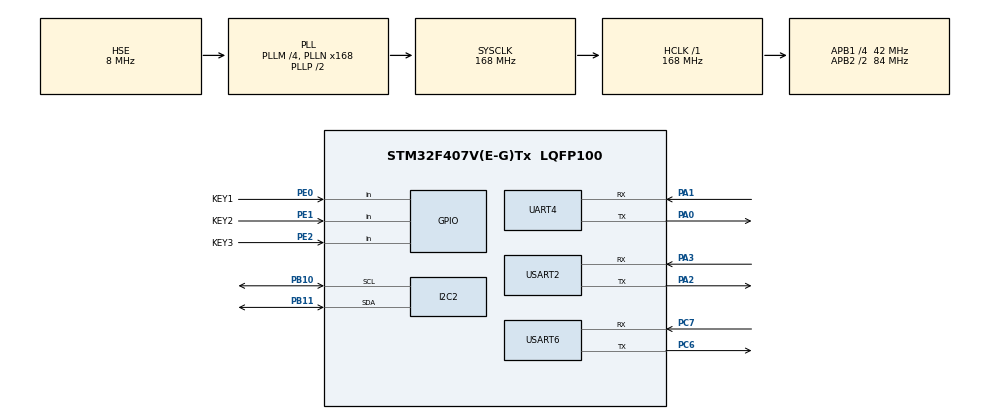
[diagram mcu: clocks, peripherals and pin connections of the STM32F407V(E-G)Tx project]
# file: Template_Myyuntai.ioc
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Dma.Request0=UART4_RX
Dma.Request1=USART2_RX
Dma.Request2=USART6_RX
Dma.UART4_RX.0.Direction=DMA_PERIPH_TO_MEMORY
Dma.UART4_RX.0.FIFOMode=DMA_FIFOMODE_DISABLE
Dma.UART4_RX.0.Instance=DMA1_Stream2
Dma.UART4_RX.0.MemDataAlignment=DMA_MDATAALIGN_BYTE
Dma.UART4_RX.0.MemInc=DMA_MINC_ENABLE
Dma.UART4_RX.0.Mode=DMA_NORMAL
Dma.UART4_RX.0.PeriphDataAlignment=DMA_PDATAALIGN_BYTE
Dma.UART4_RX.0.PeriphInc=DMA_PINC_DISABLE
Dma.UART4_RX.0.Priority=DMA_PRIORITY_LOW
Dma.USART2_RX.1.Direction=DMA_PERIPH_TO_MEMORY
Dma.USART2_RX.1.FIFOMode=DMA_FIFOMODE_DISABLE
Dma.USART2_RX.1.Instance=DMA1_Stream5
Dma.USART2_RX.1.MemDataAlignment=DMA_MDATAALIGN_BYTE
Dma.USART2_RX.1.MemInc=DMA_MINC_ENABLE
Dma.USART2_RX.1.Mode=DMA_NORMAL
Dma.USART2_RX.1.PeriphDataAlignment=DMA_PDATAALIGN_BYTE
Dma.USART2_RX.1.PeriphInc=DMA_PINC_DISABLE
Dma.USART2_RX.1.Priority=DMA_PRIORITY_LOW
Dma.USART6_RX.2.Direction=DMA_PERIPH_TO_MEMORY
Dma.USART6_RX.2.FIFOMode=DMA_FIFOMODE_DISABLE
Dma.USART6_RX.2.Instance=DMA2_Stream1
Dma.USART6_RX.2.MemDataAlignment=DMA_MDATAALIGN_BYTE
Dma.USART6_RX.2.MemInc=DMA_MINC_ENABLE
Dma.USART6_RX.2.Mode=DMA_NORMAL
Dma.USART6_RX.2.PeriphDataAlignment=DMA_PDATAALIGN_BYTE
Dma.USART6_RX.2.PeriphInc=DMA_PINC_DISABLE
Dma.USART6_RX.2.Priority=DMA_PRIORITY_LOW
Mcu.Family=STM32F4
Mcu.Name=STM32F407V(E-G)Tx
Mcu.Package=LQFP100
NVIC.DMA1_Stream2_IRQn=true\:0\:0\:false\:false\:true\:false\:true\:true
NVIC.DMA1_Stream5_IRQn=true\:0\:0\:false\:false\:true\:false\:true\:true
NVIC.DMA2_Stream1_IRQn=true\:0\:0\:false\:false\:true\:false\:true\:true
NVIC.PriorityGroup=NVIC_PRIORITYGROUP_4
NVIC.TIM2_IRQn=true\:0\:0\:false\:false\:true\:true\:true\:true
NVIC.UART4_IRQn=true\:2\:0\:true\:false\:true\:true\:true\:true
NVIC.USART2_IRQn=true\:2\:0\:true\:false\:true\:true\:true\:true
NVIC.USART6_IRQn=true\:0\:0\:false\:false\:true\:true\:true\:true
PA0-WKUP.Mode=Asynchronous
PA0-WKUP.Signal=UART4_TX
PA1.Mode=Asynchronous
PA1.Signal=UART4_RX
PA2.Mode=Asynchronous
PA2.Signal=USART2_TX
PA3.Mode=Asynchronous
PA3.Signal=USART2_RX
PB10.Mode=I2C
PB10.Signal=I2C2_SCL
PB11.Mode=I2C
PB11.Signal=I2C2_SDA
PC14-OSC32_IN.Mode=LSE-External-Oscillator
PC14-OSC32_IN.Signal=RCC_OSC32_IN
PC15-OSC32_OUT.Mode=LSE-External-Oscillator
PC15-OSC32_OUT.Signal=RCC_OSC32_OUT
PC6.Mode=Asynchronous
PC6.Signal=USART6_TX
PC7.Mode=Asynchronous
PC7.Signal=USART6_RX
PE0.GPIO_Label=KEY1
PE0.GPIO_PuPd=GPIO_PULLUP
PE0.Signal=GPIO_Input
PE1.GPIO_Label=KEY2
PE1.GPIO_PuPd=GPIO_PULLUP
PE1.Signal=GPIO_Input
PE2.GPIO_Label=KEY3
PE2.GPIO_PuPd=GPIO_PULLUP
PE2.Signal=GPIO_Input
PH0-OSC_IN.Mode=HSE-External-Oscillator
PH0-OSC_IN.Signal=RCC_OSC_IN
PH1-OSC_OUT.Mode=HSE-External-Oscillator
PH1-OSC_OUT.Signal=RCC_OSC_OUT
ProjectManager.HeapSize=0x400
ProjectManager.StackSize=0x800
ProjectManager.TargetToolchain=MDK-ARM V5.32
RCC.48MHZClocksFreq_Value=84000000
RCC.AHBFreq_Value=168000000
RCC.APB1CLKDivider=RCC_HCLK_DIV4
RCC.APB1Freq_Value=42000000
RCC.APB1TimFreq_Value=84000000
RCC.APB2CLKDivider=RCC_HCLK_DIV2
RCC.APB2Freq_Value=84000000
RCC.APB2TimFreq_Value=168000000
RCC.CortexFreq_Value=168000000
RCC.HCLKFreq_Value=168000000
RCC.HSE_VALUE=8000000
RCC.HSI_VALUE=16000000
RCC.PLLM=4
RCC.PLLN=168
RCC.PLLSourceVirtual=RCC_PLLSOURCE_HSE
RCC.SYSCLKFreq_VALUE=168000000
RCC.SYSCLKSource=RCC_SYSCLKSOURCE_PLLCLK
RCC.VCOOutputFreq_Value=336000000
TIM2.AutoReloadPreload=TIM_AUTORELOAD_PRELOAD_ENABLE
TIM2.Period=1000-1
TIM2.Prescaler=42-1
UART4.VirtualMode=Asynchronous
USART2.VirtualMode=VM_ASYNC
USART6.VirtualMode=VM_ASYNC
VP_TIM2_VS_ClockSourceINT.Mode=Internal
board=custom

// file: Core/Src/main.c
/* USER CODE BEGIN Header */
/**
  ******************************************************************************
  * @file           : main.c
  * @brief          : Main program body
  ******************************************************************************
  * @attention
  *
  * Copyright (c) 2025 STMicroelectronics.
  * All rights reserved.
  *
  * This software is licensed under terms that can be found in the LICENSE file
  * in the root directory of this software component.
  * If no LICENSE file comes with this software, it is provided AS-IS.
  *
  ******************************************************************************
  */
/* USER CODE END Header */
#include "main.h"
#include "dma.h"
#include "i2c.h"
#include "tim.h"
#include "usart.h"
#include "gpio.h"

/* USER CODE BEGIN Includes */
#include "bsp_system.h"
/* USER CODE END Includes */

void SystemClock_Config(void);

int main(void)
{

  /* MCU Configuration--------------------------------------------------------*/

  /* Reset of all peripherals, Initializes the Flash interface and the Systick. */
  HAL_Init();

  /* Configure the system clock */
  SystemClock_Config();

  /* Initialize all configured peripherals */
  MX_GPIO_Init();
  MX_DMA_Init();
  MX_UART4_Init();
  MX_USART2_UART_Init();
  MX_I2C2_Init();
  MX_TIM2_Init();
  MX_USART6_UART_Init();
  /* USER CODE BEGIN 2 */
  HAL_Delay(200);
  OLED_Init();
  My_UartInit();
  My_TIM_Init();
  Emm_V5_En_Control(&huart2, 0x01, true, 0);
  Emm_V5_En_Control(&huart4, 0x01, true, 0);
  scheduler_init();
  /* USER CODE END 2 */

  /* Infinite loop */
  /* USER CODE BEGIN WHILE */
  while (1)
  {

      scheduler_run();
    /* USER CODE END WHILE */

  }
}

void SystemClock_Config(void)
{
  RCC_OscInitTypeDef RCC_OscInitStruct = {0};
  RCC_ClkInitTypeDef RCC_ClkInitStruct = {0};

  /** Configure the main internal regulator output voltage
  */
  __HAL_RCC_PWR_CLK_ENABLE();
  __HAL_PWR_VOLTAGESCALING_CONFIG(PWR_REGULATOR_VOLTAGE_SCALE1);

  /** Initializes the RCC Oscillators according to the specified parameters
  * in the RCC_OscInitTypeDef structure.
  */
  RCC_OscInitStruct.OscillatorType = RCC_OSCILLATORTYPE_HSE;
  RCC_OscInitStruct.HSEState = RCC_HSE_ON;
  RCC_OscInitStruct.PLL.PLLState = RCC_PLL_ON;
  RCC_OscInitStruct.PLL.PLLSource = RCC_PLLSOURCE_HSE;
  RCC_OscInitStruct.PLL.PLLM = 4;
  RCC_OscInitStruct.PLL.PLLN = 168;
  RCC_OscInitStruct.PLL.PLLP = RCC_PLLP_DIV2;
  RCC_OscInitStruct.PLL.PLLQ = 4;
  if (HAL_RCC_OscConfig(&RCC_OscInitStruct) != HAL_OK)
  {
    Error_Handler();
  }

  /** Initializes the CPU, AHB and APB buses clocks
  */
  RCC_ClkInitStruct.ClockType = RCC_CLOCKTYPE_HCLK|RCC_CLOCKTYPE_SYSCLK
                              |RCC_CLOCKTYPE_PCLK1|RCC_CLOCKTYPE_PCLK2;
  RCC_ClkInitStruct.SYSCLKSource = RCC_SYSCLKSOURCE_PLLCLK;
  RCC_ClkInitStruct.AHBCLKDivider = RCC_SYSCLK_DIV1;
  RCC_ClkInitStruct.APB1CLKDivider = RCC_HCLK_DIV4;
  RCC_ClkInitStruct.APB2CLKDivider = RCC_HCLK_DIV2;

  if (HAL_RCC_ClockConfig(&RCC_ClkInitStruct, FLASH_LATENCY_5) != HAL_OK)
  {
    Error_Handler();
  }
}

void Error_Handler(void)
{
  __disable_irq();
  while (1)
  {
  }
}
